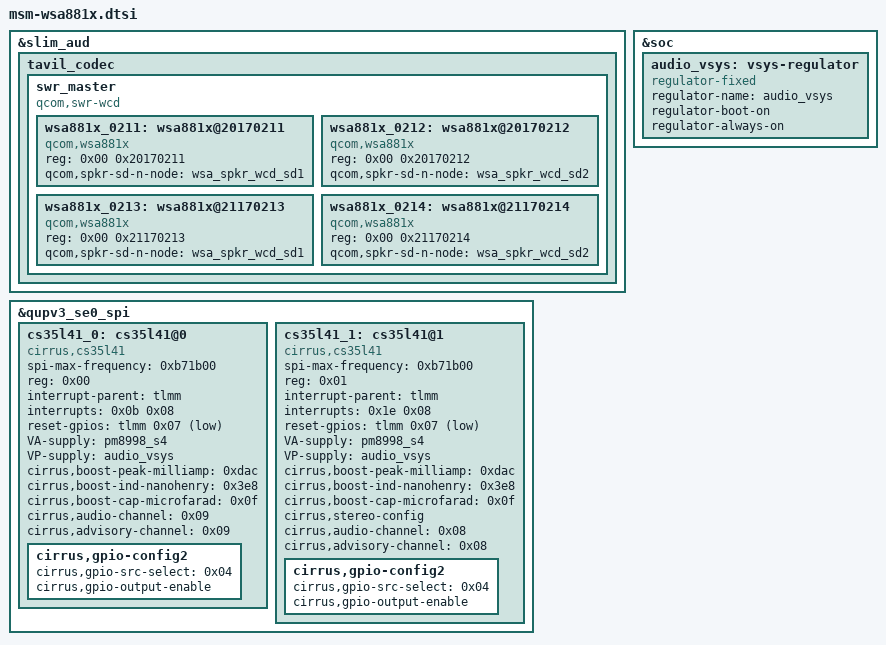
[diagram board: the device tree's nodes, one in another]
/* Copyright (c) 2016-2017, The Linux Foundation. All rights reserved.
 *
 * This program is free software; you can redistribute it and/or modify
 * it under the terms of the GNU General Public License version 2 and
 * only version 2 as published by the Free Software Foundation.
 *
 * This program is distributed in the hope that it will be useful,
 * but WITHOUT ANY WARRANTY; without even the implied warranty of
 * MERCHANTABILITY or FITNESS FOR A PARTICULAR PURPOSE.  See the
 * GNU General Public License for more details.
 */

&slim_aud {
	tavil_codec {
		swr_master {
			compatible = "qcom,swr-wcd";
			#address-cells = <2>;
			#size-cells = <0>;

			wsa881x_0211: wsa881x@20170211 {
				compatible = "qcom,wsa881x";
				reg = <0x00 0x20170211>;
				qcom,spkr-sd-n-node = <&wsa_spkr_wcd_sd1>;
			};

			wsa881x_0212: wsa881x@20170212 {
				compatible = "qcom,wsa881x";
				reg = <0x00 0x20170212>;
				qcom,spkr-sd-n-node = <&wsa_spkr_wcd_sd2>;
			};

			wsa881x_0213: wsa881x@21170213 {
				compatible = "qcom,wsa881x";
				reg = <0x00 0x21170213>;
				qcom,spkr-sd-n-node = <&wsa_spkr_wcd_sd1>;
			};

			wsa881x_0214: wsa881x@21170214 {
				compatible = "qcom,wsa881x";
				reg = <0x00 0x21170214>;
				qcom,spkr-sd-n-node = <&wsa_spkr_wcd_sd2>;
			};
		};
	};
};

&soc {
	audio_vsys: vsys-regulator {
		compatible = "regulator-fixed";
		regulator-name = "audio_vsys";
		regulator-boot-on;
		regulator-always-on;
	};
};

&qupv3_se0_spi {
	cs35l41_0: cs35l41@0 {
		#sound-dai-cells = <0x01>;
		compatible = "cirrus,cs35l41";
		spi-max-frequency = <0xb71b00>;
		reg = <0x00>;
		interrupt-parent = <&tlmm>;
		interrupts = <0x0b 0x08>;
		reset-gpios = <&tlmm 0x07 0x01>;
		VA-supply = <&pm8998_s4>;
		VP-supply = <&audio_vsys>;
		cirrus,boost-peak-milliamp = <0xdac>;
		cirrus,boost-ind-nanohenry = <0x3e8>;
		cirrus,boost-cap-microfarad = <0x0f>;
		cirrus,audio-channel = <0x09>;
		cirrus,advisory-channel = <0x09>;

		cirrus,gpio-config2 {
			cirrus,gpio-src-select = <0x04>;
			cirrus,gpio-output-enable;
		};
	};
};

&qupv3_se0_spi {
	cs35l41_1: cs35l41@1 {
		#sound-dai-cells = <0x01>;
		compatible = "cirrus,cs35l41";
		spi-max-frequency = <0xb71b00>;
		reg = <0x01>;
		interrupt-parent = <&tlmm>;
		interrupts = <0x1e 0x08>;
		reset-gpios = <&tlmm 0x07 0x01>;
		VA-supply = <&pm8998_s4>;
		VP-supply = <&audio_vsys>;
		cirrus,boost-peak-milliamp = <0xdac>;
		cirrus,boost-ind-nanohenry = <0x3e8>;
		cirrus,boost-cap-microfarad = <0x0f>;
		cirrus,stereo-config;
		cirrus,audio-channel = <0x08>;
		cirrus,advisory-channel = <0x08>;

		cirrus,gpio-config2 {
			cirrus,gpio-src-select = <0x04>;
			cirrus,gpio-output-enable;
		};
	};
};
